# AE302F80F55D5AE_CM55_HE_View register map
Vendor: Alif Semiconductor; Series: E3; File version: 1.0
CPU: CM55 r1p0, selectable endian, MPU, FPU, double-precision FPU, DSP, VTOR, 8 interrupt priority bits, 1 SAU regions
Registers are 32-bit, read-write, reset 0x0 unless marked. A register's access mark holds for its fields unless they carry their own. Offsets are from the block's base; [hi:lo] are bit positions; {n}, {i} and the like mark numbered series.

## DAC120
Base 0x49028000
Same registers: DAC121 0x49029000
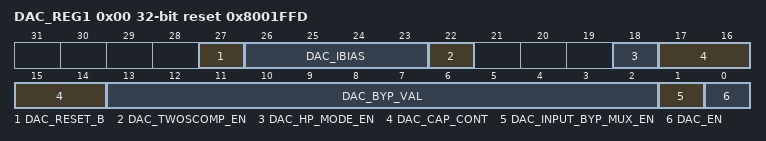
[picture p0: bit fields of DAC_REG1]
0x00 DAC_REG1 reset 0x8001FFD (reset mask 0xF8783FFF) — REG1 DAC Control Register
  [27] DAC_RESET_B — DAC reset:
    0=Reset asserted; 1=Reset released
  [26:23] DAC_IBIAS — Trims buffer output current (HP mode): From 0000 = 0 uA to 1111 = 1.5 mA Default is 1111 for DAC120 and 0000 for DAC121 Step size ~100 uA
  [22] DAC_TWOSCOMP_EN — Converts two's complement to unsigned binary data:
    0=Input data is unsigned; 1=Input data is two's complement signed (conversion to unsigned enable)
  [18] DAC_HP_MODE_EN — DAC high-performance mode enable.
    0=Low-power (LP) mode (default for DAC121); 1=High-performance (HP) mode (default for DAC120)
  [17:14] DAC_CAP_CONT — Trims HP mode capacitance compensation: From xx00 = 2 pF to xx11 = 8 pF Step size = 2 pF Default is xx11 = 8 pF for DAC120 and xx00 for DAC121 Bits [17-16] = Don't care
  [13:2] DAC_BYP_VAL — DAC input data in bypass mode
  [1] DAC_INPUT_BYP_MUX_EN — Selects DAC input data source:
    0=DAC_IN register; 1=DAC_REG1[DAC_BYP_VAL] bitfield (bypass mode)
  [0] DAC_EN — DAC enable:
    0=DAC is disabled; 1=DAC is enabled
0x04 DAC_IN — DAC Input Value Register
  [11:0] VALUE — Value used by DAC analog portion for conversion.

## HWSEM0
Base 0x4902E000
Same registers: HWSEM{n} {0x4902E000+0x10*n} (n=1..15)
0x00 HWSEM_REQ_REG reset not defined — Request register
  [31:0] REQ_ACQ — Request a HWSEM module by writing the processor ID into this field. Check the status of the HWSEM request by reading this field.
0x04 HWSEM_REL_REG reset not defined — Release register
  [31:0] REL_CHK — Release the HWSEM by writing the processor ID into this field. Check the current HWSEM count by reading this field.
0x08 HWSEM_RST_REG wo reset not defined — Reset register
  [31:0] RST — Reset the semaphore count and current master ID.

## CAN_CNT
Base 0x49037000
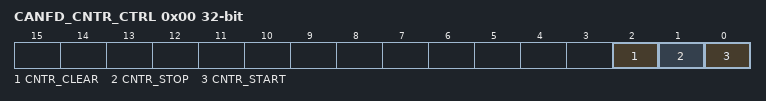
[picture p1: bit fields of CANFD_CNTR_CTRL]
0x00 CANFD_CNTR_CTRL wo — CANFD Counter Control Register
  [2] CNTR_CLEAR — Clear the CANFD counter.
  [1] CNTR_STOP — Stop the CANFD counter.
  [0] CNTR_START — Start the CANFD counter.
0x04 CANFD_CNTR_LOW — CANFD Counter Low Register
  [31:0] CNTR_LO — CANFD counter bits [31:0].
0x08 CANFD_CNTR_HIGH — CANFD Counter High Register
  [31:0] CNTR_HI — CANFD counter bits [63:32].

## AES0
Base 0x83001000
Same registers: AES1 0x83003000
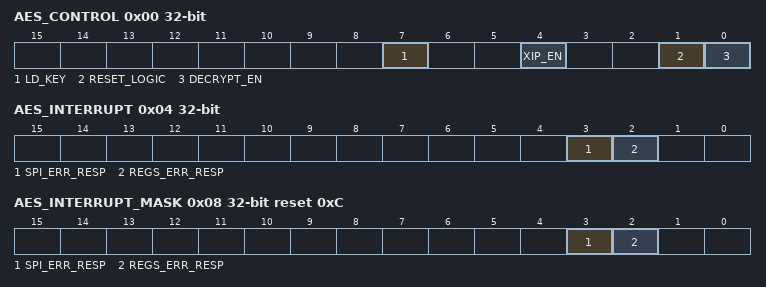
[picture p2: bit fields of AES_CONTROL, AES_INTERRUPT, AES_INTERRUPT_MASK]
0x00 AES_CONTROL
  [7] LD_KEY — Write 1 once the new key has been written by the Secure Enclave, so the key can be pre-processed by the AES engine. Read returns 0x0.
  [4] XIP_EN — When this bit is set, the OSPI can be used in XIP mode directly, with or without intervention from the decryption logic.
  [1] RESET_LOGIC — Reset the AES engine.
  [0] DECRYPT_EN — Decryption Enabled When set, this bit causes host read accesses to use the decryption logic rather than go directly to the OSPI module. Note that the OSPI module must be programmed to work in XIP mode prior to setting this bit.
0x04 AES_INTERRUPT — AES Interrupt Control Register
  [3] SPI_ERR_RESP — SPI Error Response interrupt enabling. Set when an error response is received from the OSPI through the AHB bus. Write 1 to clear bit.
    0=SPI Error Response interrupt is disabled; 1=SPI Error Response interrupt is enabled
  [2] REGS_ERR_RESP — Register Error Response interrupt enabling. Set when there is an access to an invalid AES register. Write 1 to clear bit.
    0=Register Error Response interrupt is disabled; 1=Register Error Response interrupt is enabled
0x08 AES_INTERRUPT_MASK reset 0xC
  [3] SPI_ERR_RESP — Mask for the SPI Error Response interrupt.
    0=SPI Error Response interrupt is not masked; 1=SPI Error Response interrupt is masked
  [2] REGS_ERR_RESP — Mask for the Register Error Response interrupt.
    0=Register Error Response interrupt is not masked; 1=Register Error Response interrupt is masked
0x20 AES_RXDS_DELAY 8-bit — OSPI RXDS Delay Register
  [4:0] RXDS_DELAY — A delay added to the OSPI RXDS input signal in 0.5-ns steps. The maximum allowed value to program is 16. NOTE: The delay should be set to overcome the internal 3.6 ns delay of OSPI data lines compared to the RXDS line. The objective is to ensure that RXDS is delayed by 1/4 OSPI clock cycle with respect to the leading edge of the valid data lines. The nominal delay code for 100 MHz operation should be set to 12, resulting in approximately 6 ns delay for the RXDS line. This value may need to be calibrated for each specific application.
    0=No delay; 1=0.5 ns delay; 2=2 x 0.5 ns delay; 15=15 x 0.5 ns delay; 16=16 x 0.5 ns delay

## M55HE_NVIC_S
Base 0xE000E100
Same registers: M55HE_NVIC_NS 0xE002E100
{0x0+4i} NVIC_ISER[{i}] (i=0..14) — Interrupt Set-Enable Register (n)
  [31:0] SETENA — Allows to enable an interrupt or read the status. For each bit: Read 0x0: Interrupt is disabled Read 0x1: Interrupt is enabled Write 0x0: No effect Write 0x1: Enable interrupt
{0x80+4i} NVIC_ICER[{i}] (i=0..14) — Interrupt Clear-Enable Register (n)
  [31:0] CLRENA — Allows to disable an interrupt or read the status. For each bit: Read 0x0: Interrupt is disabled Read 0x1: Interrupt is enabled Write 0x0: No effect Write 0x1: Disable interrupt
{0x100+4i} NVIC_ISPR[{i}] (i=0..14) — Interrupt Set-Pending Register (n)
  [31:0] SETPEND — Allows to set an interrupt to pending state or read the status. For each bit: Read 0x0: Interrupt is not pending Read 0x1: Interrupt is pending Write 0x0: No effect Write 0x1: Set interrupt to pending state
{0x180+4i} NVIC_ICPR[{i}] (i=0..14) — Interrupt Clear-Pending Register (n)
  [31:0] CLRPEND — Allows to clear an interrupt to not pending state or read the status. For each bit: Read 0x0: Interrupt is not pending Read 0x1: Interrupt is pending Write 0x0: No effect Write 0x1: Clear pending state of interrupt
{0x200+4i} NVIC_IABR[{i}] (i=0..14) ro — Interrupt Active Bit Register (n)
  [31:0] ACTIVE — Indicates the active state of an interrupt. For each bit:
    0=Interrupt is not active; 1=Interrupt is active
{0x280+4i} NVIC_ITNS[{i}] (i=0..14) — Interrupt Target Non-Secure Register (n)
  [31:0] ITNS — Determines whether an interrupt targets non-secure or secure state. For each bit:
    0=Interrupt targets secure state; 1=Interrupt targets non-secure state
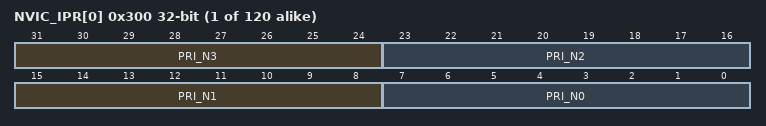
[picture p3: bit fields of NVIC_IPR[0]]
{0x300+4i} NVIC_IPR[{i}] (i=0..119) — Interrupt Priority Register (n)
  [31:24] PRI_N3 — Allows to set or read the priority level for interrupt 3
  [23:16] PRI_N2 — Allows to set or read the priority level for interrupt 2
  [15:8] PRI_N1 — Allows to set or read the priority level for interrupt 1
  [7:0] PRI_N0 — Allows to set or read the priority level for interrupt 0
    0=Priority level is 0 (highest); 1=Priority level is 1; 255=Priority level is 255 (lowest)
